AUTOSAR XML (schema 314)
package /ComponentType
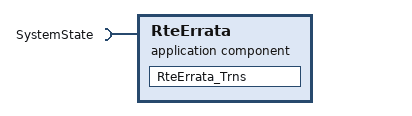
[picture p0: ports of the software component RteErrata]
  application software component type RteErrata  # This SWC contains definitions required to workaround Rte Generation errata following: 1) ESCAN00059438AN00059438 (corrected in Rte 2.22.00)
    require port SystemState: required-interface=SystemState
  internal behavior RteErrata_InternalBehavior: component=RteErrata, port-api-option{enable-take-address=false, indirect-api=false, port=SystemState}
    4 x mode switch event, all with start-on-event=RteErrata_Trns, activation=ENTRY:
      MST_RteErrata_Trns_0: mode=SystemState.Mode.DISABLE
      MST_RteErrata_Trns_1: mode=SystemState.Mode.OFF
      MST_RteErrata_Trns_2: mode=SystemState.Mode.OPERATE
      MST_RteErrata_Trns_3: mode=SystemState.Mode.WARMINIT
    runnable RteErrata_Trns
  swc implementation RteErrata_Implementation: behavior=RteErrata_InternalBehavior
    code-descriptors:
      code Code: type=SRC
